# psoc4100smax register map
Vendor: Cypress Semiconductor; Series: PSoC4100Smax; File version: 1.0
CPU: CM0PLUS r0p1, little endian, MPU, no FPU, VTOR, 2 interrupt priority bits
Registers are 32-bit, read-write, reset 0x0 unless marked. A register's access mark holds for its fields unless they carry their own. Offsets are from the block's base; [hi:lo] are bit positions; {n}, {i} and the like mark numbered series; 'fields as' and 'values as' point back to an identical list.

## MSC0 (part 1 of 2) — MultiSense Controller
Base 0x40290000
Same registers: MSC1 0x402A0000
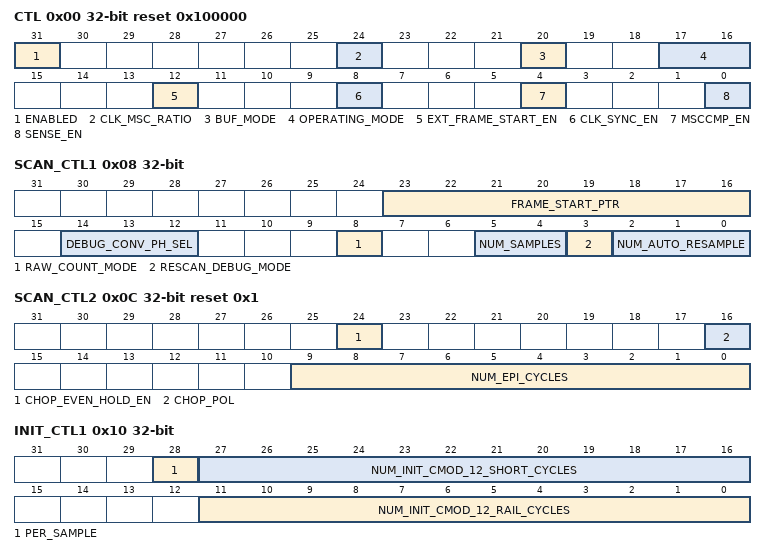
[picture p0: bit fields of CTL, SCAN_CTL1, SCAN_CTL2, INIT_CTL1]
0x00 CTL reset 0x100000 — Configuration and Control
  [31] ENABLED — Master enable of the MSCv3 IP. Must be set to '1' for any operation to function. When '0' all analog components are off and all switches are open.
    0=DISABLED (N/A); 1=ENABLED (N/A)
  [24] CLK_MSC_RATIO — Control bit for logic that creates clk_msc from clk_hf. '0': Divided. clk_hf :: clk_msc is at least 2:1 divide ratio. Ratio controlled by clock_msc_pos_en and clock_msc_neg_en provided by PERI. '1': Pass-through. clk_hf :: clk_msc is 1:1.
    0=DIVIDED (N/A); 1=PASSTHROUGH (N/A)
  [20] BUF_MODE — Shield buffer operating mode select. '0': High bandwidth mode. '1': Shield mode.
    0=HIGH_BW_MODE (N/A); 1=SHIELD_MODE (N/A)
  [17:16] OPERATING_MODE — Sequencer FSM Operating Mode '0': CPU Mode. '1': Chained-Scan DMA Mode. '2': Autonomous Scan Multi Sensor Mode. '3': Low Power Always-On-Capsense Mode.
    0=CPU (Frame scan configurations are stored in system RAM. Start of frame initiated by CPU via AHB. After each scan in frame, the end of scan interrupt is raised. The CPU extracts results and programs and starts the next scan. End of frame interrupt is produced so CPU can extract and process data.); 1=CS_DMA (Frame scan configurations are stored in system RAM. CPU writes into DMA registers to start a DMA transfer. i.e. CPU/firmware initiates a DMA transfer to write first scan configuration. The rest of the scans in the frame are chained via trigger to DMA. End of frame interrupt is produced so CPU can extract and process data.); 2=AS_MS (Frame scan configurations are stored in IP RAM. Start of frame initiated by CPU via AHB. The rest of the scans are chained autonomously by Sequencer FSM. End of frame interrupt is produced so CPU can extract and process data.); 3=LP_AOC (Frame scan configurations are stored in IP RAM. Start of frame initiated by LP-AOC timer expire. Rest of the scans are chained autonomously by Sequencer FSM. No end of frame interrupt, no data processing by CPU. Wake up interrupt fired upon valid signal detection (LP-AOC FSM).)
  [12] EXT_FRAME_START_EN — Control bit to enable external frame start of Sequencer FSM via GPIO. '0': FSM is only sensitive to START_FRAME bit. '1': FSM sensitive to external frame start (and not sensitive to START_FRAME). This external start can be a new or pending external frame start event or an indication from the LP-AoC FSM.
    0=DISABLED (N/A); 1=ENABLED (N/A)
  [8] CLK_SYNC_EN — Control bit to create external channel sync clock. '0': msc_ext_sync_clk_out (and _out_en) tied 0. '1': Generate msc_ext_sync_clk_out using clock_sync_pos_en and set msc_ext_sync_clk_out_en = 1.
    0=DISABLED (N/A); 1=ENABLED (N/A)
  [4] MSCCMP_EN — MSC Comparator Enable.
    0=DISABLED (N/A); 1=ENABLED (N/A)
  [0] SENSE_EN — Enables the sense modulator output. '0': All switches, static or dynamic, are open. '1': Switches can be closed/open as per MMIO setting and Sequencer FSM.
    0=DISABLED (N/A); 1=ENABLED (N/A)
0x04 SPARE — Spare MMIO
  [5:0] SPARE — Spare MMIO (Hard IP).
0x08 SCAN_CTL1 — Scan Control 1
  [23:16] FRAME_START_PTR — Pointer to first sensor configuration of a frame. Hardware increments a local pointer from this start point. In LP-AoC mode, hardware returns to this pointer after the frame is complete prior to starting the next frame (after a timeout).
  [14:12] DEBUG_CONV_PH_SEL — Debug counter conversion chop phase select for DEBUG_CONV_COUNT. Must be between 0 and NUM_CONV. The number of conversions (or chop phases) for a given scan is controlled by NUM_CONV. Although only discrete values are possible for NUM_CONV, any conversion index up to this number may be selected up to NUM_CONV. For example if NUM_CONV = 7 (number of conversions is 8), then DEBUG_CONG_PH_SEL can be any value between 0 and 7 to select the particular conversion that the count is required for.
  [8] RAW_COUNT_MODE — Control bit to handle behaviour when RAW_COUNT exceeds 0xFFFF. '0': Saturate. In this scenario, RAW_COUNT is clamped at 0xFFFF and RESULT_FIFO_RD.OVERFLOW is set. '1': Overflow. In this scenario, RAW_COUNT rolls over and RESULT_FIFO_RD.OVERFLOW is set. This mode allows more sensitive tuning if measuring baseline capacitance is a don't care (e.g. SAR use case).
    0=SATURATE (N/A); 1=OVERFLOW (N/A)
  [5:4] NUM_SAMPLES — Number of samples (minus 1) to be scanned. NUM_SAMPLES > 1 results in autonomous scan same sensor (AS-SS) behaviour. Firmware Rule: Usable setting for NUM_SAMPLES is limited depending on the size of the result FIFO. Size of this FIFO determined by CONFIG_NR and SAMPLE_NR. If CONFIG_NR = 0, FIFO size is SAMPLE_NR. If CONFIG_NR > 0, FIFO size is SAMPLE_NR * CONFIG_NR. NUM_SAMPLES must be less than or equal to the FIFO size in debug mode.
  [3] RESCAN_DEBUG_MODE — If this bit is set all results (good and bad) generated by NUM_AUTO_RESAMPLE are stored. Debug feature. Firmware Rule: Usable setting for NUM_AUTO_RESAMPLE is limited depending on the size of the result FIFO. Size of this FIFO determined by CONFIG_NR and SAMPLE_NR. If CONFIG_NR = 0, FIFO size is SAMPLE_NR. If CONFIG_NR > 0, FIFO size is SAMPLE_NR * CONFIG_NR. NUM_AUTO_RESAMPLE must be less than or equal to the FIFO size in debug mode.
    0=DISABLED (N/A); 1=ENABLED (N/A)
  [2:0] NUM_AUTO_RESAMPLE — If Sequencer detects a bad conversion and NUM_AUTO_RESAMPLE != 0, it will not store the bad result. Instead, it will automatically re-sample using current configuration without firmware intervention. This process repeats until a good conversion is produced or until the programmed maximum. If bad samples are produces for each programmed re-sample attempt, the final bad sample is stored.
0x0C SCAN_CTL2 reset 0x1 — Scan Control 2
  [24] CHOP_EVEN_HOLD_EN — Use this bit to hold the chop value at the end of every even chop phase of NUM_CONV.
    0=DISABLED (N/A); 1=ENABLED (N/A)
  [16] CHOP_POL — Polarity of first chop phase. Hardware updates chop control locally from this point (via inversion and following CHOP_EVEN_HOLD_EN programming also).
  [9:0] NUM_EPI_CYCLES — Number of clk_mod cycles to be run during EPILOGUE. Note that setting this register to 0 is an illegal configuration. This guarantees at least 1 clk_mod cycle during EPILOGUE (required to help timing closure in Sequencer FSM).
0x10 INIT_CTL1 — Initialisation Control 1
  [28] PER_SAMPLE — Decides if coarse initialisation is done per sample when NUM_SAMPLES > 0 (i.e. more than one sample per scan). Applies to CMOD_SEL selected Cmod.
    0=DISABLED (N/A); 1=ENABLED (N/A)
  [27:16] NUM_INIT_CMOD_12_SHORT_CYCLES — Duration of the coarse short phase (shorting Cmod1 and Cmod2 in full-wave mode). Programmed in terms of clk_mod cycles. Should be set to zero in the case of half-wave mode.
  [11:0] NUM_INIT_CMOD_12_RAIL_CYCLES — Duration of the coarse initialisation phase (e.g. connecting Cmod1 to vdda and Cmod2 to vssa in full-wave mode). Programmed in terms of clk_mod cycles.
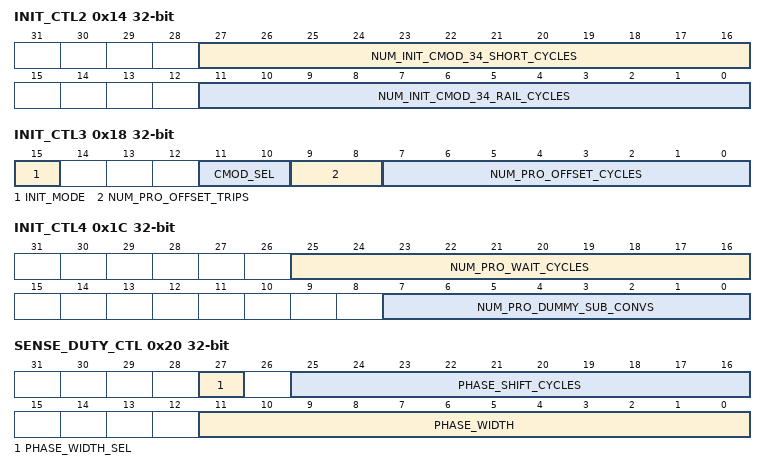
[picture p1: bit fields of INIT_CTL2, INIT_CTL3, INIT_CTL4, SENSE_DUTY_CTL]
0x14 INIT_CTL2 — Initialisation Control 2
  [27:16] NUM_INIT_CMOD_34_SHORT_CYCLES — Duration of the coarse short phase (shorting Cmod3 and Cmod4 in full-wave mode). Programmed in terms of clk_mod cycles. Should be set to zero in the case of half-wave mode.
  [11:0] NUM_INIT_CMOD_34_RAIL_CYCLES — Duration of the coarse initialisation phase (e.g. connecting Cmod3 to vdda and Cmod4 to vssa in full-wave mode). Programmed in terms of clk_mod cycles.
0x18 INIT_CTL3 — Initialisation Control 3
  [15] INIT_MODE — Determines autonomous initialisation behaviour during INIT_CMOD. 0: Decode CMOD_SEL. CMOD_12: S1CV = 1, S2CG = 1 CMOD_34: S3CV = 1, S4CG = 1 CMOD_1: S1CV = 1 CMOD_3: S3CV = 1 1: Decode CMOD_SEL. Should be CMOD_1 or CMOD_3. Firmware Rule: Firmware should also close CBSO, FSP and one of BGRF/RMF/MBF to select type of reference. CMOD_1: C1CB = 1 CMOD_3: C3CB = 1
    0=REFERENCE_VDDA (Used for full and half wave when Vdda is reference.); 1=REFERENCE_VREF (Used for half-wave when Vref is reference.)
  [11:10] CMOD_SEL — Select which Cmod are used and the cycle thresholds to be used for coarse initialisation. Note this field affects which Cmod switches are autonomously initialised by hardware as well as influencing the cycle counters as per INIT_MODE. '0' || '2': Use NUM_INIT_CMOD_12_RAIL_CYCLES and NUM_INIT_CMOD_12_SHORT_CYCLES '1' || '3': Use NUM_INIT_CMOD_34_RAIL_CYCLES and NUM_INIT_CMOD_34_SHORT_CYCLES Firmware Rule: Firmware must program the appropriate SNS_SW_SEL_CMODx.ENABLED bits to match the Cmod selected with CMOD_SEL. Firmware must also set a valid INIT_MODE with CMOD_SEL.
    0=CMOD_12 (Used for full-wave); 1=CMOD_34 (Used for full-wave); 2=CMOD_1 (Used for half-wave); 3=CMOD_3 (Used for half-wave)
  [9:8] NUM_PRO_OFFSET_TRIPS — Number of comparator trips required to be observed in PRO_OFFSET before proceeding to dummy cycles. Note that a 'trip' is defined as a change of state of the comparator (either a 0 to 1 or a 1 to 0 transition). A trip at the very start of PRO_OFFSET is considered a trip with respect to this count.
  [7:0] NUM_PRO_OFFSET_CYCLES — Maximum number of clk_mod cycles to be assigned for the PRO_OFFSET state. If NUM_PRO_OFFSET_TRIPS are observed before this timeout, exit at that point. Programming combinations: a) OFFSET_CYCLES == 0 && OFFSET_TRIPS == 0 -> Skip PRO_OFFSET b) OFFSET_CYCLES == 0 && OFFSET_TRIPS > 0 -> wait in PRO_OFFSET for OFFSET_TRIPS c) OFFSET_CYCLES > 0 && OFFSET_TRIPS == 0 -> wait in PRO_OFFSET for OFFSET_CYCLES d) OFFSET_CYCLES > 0 && OFFSET_TRIPS > 0 -> wait in PRO_OFFSET for the first of OFFSET_CYCLES and OFFSET_TRIPS. Note that if OFFSET_TRIPS > 0: i) SW_COTCA and SW_COCB autonomously adjust as per their description after each comparator trip apart from the last trip. Expect OFFSET_TRIPS-1 adjustments in PRO_OFFSET. ii) If FINE_MODE == COMPENSATION SW_CFTCA and SW_CFTCB autonomously swap settings after each comparator trip apart from the last trip. Expect OFFSET_TRIPS-1 adjustments in PRO_OFFSET. iii) For both sets of switches above, after the last trip the switches revert to their programmed MMIO setting when exiting PRO_OFFSET. If OFFSET_TRIPS == 0 and OFFSET_CYCLES > 0: Intention is that PRO_OFFSET be a fixed duration. The autonomous behaviour for this case is the same as the OFFSET_TRIPS > 0 case, except that the number of trips (and hence the number of adjustments for (i) and (ii) above) are unknown in advance. At the end of OFFSET_CYCLES, the switches revert to their programmed MMIO setting when exiting PRO_OFFSET.
0x1C INIT_CTL4 — Initialisation Control 4
  [25:16] NUM_PRO_WAIT_CYCLES — Number of clk_mod cycles to be run during PRO_WAIT. Firmware Rule: If chopping is enabled (NUM_CONV > ONE), then NUM_PRO_WAIT_CYCLES must be >=1.
  [7:0] NUM_PRO_DUMMY_SUB_CONVS — Number of sub-conversions (dummy cycles) to be run during PRO_DUMMY. Firmware Rule: If chopping is enabled (NUM_CONV > ONE), then NUM_PRO_DUMMY_SUB_CONVS must be >=1.
0x20 SENSE_DUTY_CTL — Sense Clock Duty Cycle Control
  [27] PHASE_WIDTH_SEL — Select which phases the PHASE_WIDTH applies to: '0': PHASE_WIDTH corresponds to width of ph0 and ph2. '1': PHASE_WIDTH corresponds to width of ph1 and ph3.
    0=PH0_AND_PH2 (N/A); 1=PH1_AND_PH3 (N/A)
  [25:16] PHASE_SHIFT_CYCLES — Phase shift cycle control for ph0X and ph1X. Must be > 0 if PHASE_SHIFT_EN = 1.
  [11:0] PHASE_WIDTH — Control width (clk_mod cycles) of ph0 and ph2 OR ph1 and ph3. If set to zero, Fs is divided equally between all phases. This field is only applicable when LFSR_MODE = DIRECT_CLOCK.
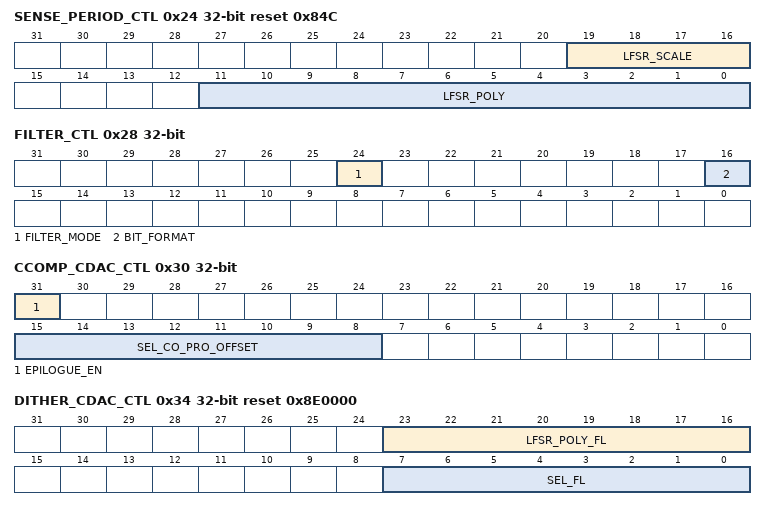
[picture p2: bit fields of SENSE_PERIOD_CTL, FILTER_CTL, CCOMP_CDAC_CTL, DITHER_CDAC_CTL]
0x24 SENSE_PERIOD_CTL reset 0x84C — Sense Clock Period Control
  [19:16] LFSR_SCALE — Shift the LFSR output left by LSFR_SCALE bits before adding to SENSE_DIV. This scaling is only applicable in spread spectrum mode. Note that the clock divider including the dithering term must fit in 12 bits, otherwise the result is undefined.
  [11:0] LFSR_POLY — Programmable polynomial to be used for the sense LFSR. For example (default): G(x) = X^12 + X^7 + X^4 + X^3 + 1 LFSR_POLY = 0x84C (1000_0100_1100). Note that LFSR_POLY[i] = 1 if X^(i+1) is included in the polynomial. The +1 feedback term is implied and doesn't need a programmable bit.
0x28 FILTER_CTL — Filter Control
  [24] FILTER_MODE
    0=CIC1 (Use the standard first order counter low pass filter (equivalent to CIC1). Scan Time = 2^M Number of CIC1 sub-samples = 1 Time for first valid CIC1 sub-sample = 2^M Number of valid CIC1 sub-samples = 1 CIC1 Scan Resolution = 2^M = N); 1=CIC2 (Use CIC2 Filter. Advantage of CIC2 over CIC1 is a higher resolution result for an equivalent scan time. All valid sub-samples are averaged to achieve an overall sample result for the scan. Interrupt is fired for every valid sub-sample to facilitate debug of the individual sub-samples. Scan Time = 2^M Number of CIC2 sub-samples = (2^M)/N Time for first valid CIC2 sub-sample = 2N Number of valid CIC2 sub-samples = ((2^M)/N) - 1 CIC2 Scan Resolution = N^2)
  [16] BIT_FORMAT — Determines how the synchronised comparator output is interpreted by the filter pipeline. Firmware Rule: When FILTER_MODE = CIC1, BIT_FORMAT should be UNSIGNED.
    0=UNSIGNED (Input values [0,+1]); 1=SIGNED (Input values [-1,+1]. In this scenario a value of 0 is interpreted as -1.)
0x30 CCOMP_CDAC_CTL — Compensation CAPDAC Control
  [31] EPILOGUE_EN — Control on whether Ccomp is active during EPILOGUE for final balancing in a conversion. Note that for this bit to enable Ccomp during EPILOGUE, need SEL_CO > 0 or FINE_MODE = COMPENSATION.
    0=DISABLED (N/A); 1=ENABLED (N/A)
  [15:8] SEL_CO_PRO_OFFSET — Select value for Compensation CAPDAC size during PRO_OFFSET until the first comparator trip is observed. Otherwise SEL_CO applies.
0x34 DITHER_CDAC_CTL reset 0x8E0000 — Flatspot/Dither CAPDAC Switch Control
  [23:16] LFSR_POLY_FL — Dither/Flatspot CAPDAC LFSR polynomial. Uses same encoding as the spread spectrum polynomial LFSR_POLY. For example (default): G(x) = X^8 + X^4 + X^3 + X^2 + 1 LFSR_POLY_FL = 0x8E (1000_1110). Note that LFSR_POLY_FL[i] = 1 if X^(i+1) is included in the polynomial. The +1 feedback term is implied and doesn't need a programmable bit.
  [7:0] SEL_FL — Select value for Dither/Flatspot CAPDAC size. If dithering is enabled (FL_EN = 1), this is the seed value for the LFSR. If dithering is disabled, this value is presented directly to the hard IP as the CAPDAC code.
0x40 CSW_CTL — Control Mux Switch Control
  [31:0] CSW_FUNC_MODE — Select between SW_SEL_CSW[x] and SW_SEL_CSW_FUNC. CSW_FUNC_MODE[x] = 0: Use SW_CSW_CTL for control MUX x. CSW_FUNC_MODE[x] = 1: Use SW_SEL_CSW_FUNC[y] for control MUX x as selected by y = {SW_SEL_CSW_MASK2[x],SW_SEL_CSW_MASK1[x],SW_SEL_CSW_MASK0[x]}.
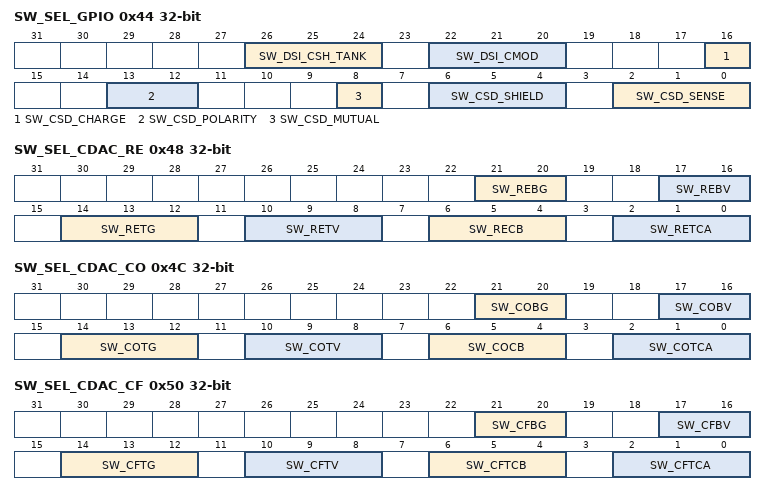
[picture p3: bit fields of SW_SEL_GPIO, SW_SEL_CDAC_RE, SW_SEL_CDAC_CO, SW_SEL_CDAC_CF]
0x44 SW_SEL_GPIO — GPIO Switch Control
  [26:24] SW_DSI_CSH_TANK — MUX select for dsi_csh_tank waveform. if CMOD_SEL = CMOD_12 | CMOD_1 dsi_csh_tank[0] = Decode SW_DSI_CSH_TANK to select appropriate dsi_csh_tank waveform. dsi_csh_tank[1] = 0. if CMOD_SEL = CMOD_34 | CMOD_3 dsi_csh_tank[0] = 0. dsi_csh_tank[1] = Decode SW_DSI_CSH_TANK to select appropriate dsi_csh_tank waveform. This is assuming that: dsi_csh_tank[0] is routed to cmod2 dsi_csh_tank[1] is routed to cmod4 Note that hardware overrides MMIO setting for dsi_csh_tank and sets it 1 during the INIT_SHORT state if using GPIO sensors (SW_DSI_CMOD != OPEN || SW_DSI_CSHTANK != OPEN).
    0=LOGIC_0 (N/A); 1=LOGIC_1 (N/A); 2=CHOP_PH0_PH1 (chop == 1 ? ph0 : ph1); 3=CHOP_PH1_PH3 (chop == 1 ? ph1 : ph3); 4=PH1 (N/A)
  [22:20] SW_DSI_CMOD — MUX select for dsi_cmod waveform. if CMOD_SEL = CMOD_12 | CMOD_1 dsi_cmod[0] = Decode SW_DSI_CMOD to select appropriate dsi_cmod waveform. dsi_cmod[1] = 0. if CMOD_SEL = CMOD_34 | CMOD_3 dsi_cmod[0] = 0. dsi_cmod[1] = Decode SW_DSI_CMOD to select appropriate dsi_cmod waveform. This is assuming that: dsi_cmod[0] is routed to cmod1 dsi_cmod[1] is routed to cmod3 Note that hardware overrides MMIO setting for dsi_cmod and sets it 1 during the INIT_SHORT state if using GPIO sensors (SW_DSI_CMOD != OPEN || SW_DSI_CSHTANK != OPEN).
    0=LOGIC_0 (N/A); 1=LOGIC_1 (N/A); 2=CHOP_PH1_PH0 (chop == 1 ? ph1 : ph0); 3=CHOP_PH3_PH1 (chop == 1 ? ph3 : ph1); 4=PH0 (N/A)
  [16] SW_CSD_CHARGE — MUX select for csd_charge waveform.
    0=LOGIC_0 (N/A); 1=LOGIC_1 (N/A)
  [13:12] SW_CSD_POLARITY — MUX select for csd_polarity waveform.
    0=LOGIC_0 (N/A); 1=LOGIC_1 (N/A); 2=PH0_OR_PH1 (N/A)
  [8] SW_CSD_MUTUAL — MUX select for csd_mutual waveform.
    0=LOGIC_0 (N/A); 1=LOGIC_1 (N/A)
  [6:4] SW_CSD_SHIELD — MUX select for csd_shield waveform.
    0=LOGIC_0 (N/A); 1=LOGIC_1 (N/A); 2=PH0 (N/A); 3=PH1 (N/A); 4=PH0_OR_PH3 (N/A); 5=PH0_OR_FS2PH1_AND_PH1_OR_PH3 (ph0 || [Fs2_ph1 && (ph1 || ph3)]); 6=PH1X (N/A)
  [2:0] SW_CSD_SENSE — MUX select for csd_sense waveform.
    0=LOGIC_0 (N/A); 1=LOGIC_1 (N/A); 2=PH0 (N/A); 3=PH1 (N/A); 4=PH0_OR_PH3 (N/A); 5=PH0X (N/A); 6=PH1X (N/A)
0x48 SW_SEL_CDAC_RE — Reference CAPDAC Switch Control
  [21:20] SW_REBG — Reference CAPDAC bottom plate to vssa_q Switch. Firmware Rule: Do not program REBV and REBG such that they are closed simultaneously.
    0=OPEN (sel = 00); 1=CLOSED (sel = 01); 2=CLK (sel = 10 (clk_reffb)); 3=CLK_BAR (sel = 11 (!clk_reffb))
  [17:16] SW_REBV — Reference CAPDAC bottom plate to vdda_q Switch. Firmware Rule: Do not program REBV and REBG such that they are closed simultaneously.
    values as SW_REBG
  [14:12] SW_RETG — Reference CAPDAC top plate to vssa_q Switch. Firmware Rule: Do not program RETV and RETG such that they are closed simultaneously.
    0=OPEN (sel = 00); 1=CLOSED (sel = 01); 2=CLK (sel = 10 (clk_reffb)); 3=CLK_BAR (sel = 11 (!clk_reffb)); 4=PH0 (DFT mode); 5=PH2 (DFT mode)
  [10:8] SW_RETV — Reference CAPDAC top plate to vdda_q Switch. Firmware Rule: Do not program RETV and RETG such that they are closed simultaneously.
    values as SW_RETG
  [6:4] SW_RECB — Reference CAPDAC to CSD Bus B Switch
    0=OPEN (sel = 00); 1=CLOSED (sel = 01); 2=CHOP_CLK_BAR (chop == 0 ? sel = 10 (clk_reffb) : sel = 11 (!clk_reffb)); 3=CHOP_CLK (chop == 1 ? sel = 10 (clk_reffb) : sel = 11 (!clk_reffb)); 4=PH1 (DFT mode (ph1 ? sel = 01 : sel = 00)); 5=PH3 (DFT mode (ph3 ? sel = 01 : sel = 00))
  [2:0] SW_RETCA — Reference CAPDAC top plate to CSD Bus A Switch
    values as SW_RECB
0x4C SW_SEL_CDAC_CO — Compensation CAPDAC Switch Control
  [21:20] SW_COBG — Compensation CAPDAC bottom plate to vssa_q Switch. Firmware Rule: Do not program COBV and COBG such that they are closed simultaneously.
    0=OPEN (sel = 00); 1=CLOSED (sel = 01); 2=CLK (sel = 10 (clk_comp)); 3=CLK_BAR (sel = 11 (!clk_comp))
  [17:16] SW_COBV — Compensation CAPDAC bottom plate to vdda_q Switch. Firmware Rule: Do not program COBV and COBG such that they are closed simultaneously.
    values as SW_COBG
  [14:12] SW_COTG — Compensation CAPDAC top plate to vssa_q Switch. Firmware Rule: Do not program COTV and COTG such that they are closed simultaneously.
    values as SW_SEL_CDAC_RE.SW_RETG
  [10:8] SW_COTV — Compensation CAPDAC top plate to vdda_q Switch. Firmware Rule: Do not program COTV and COTG such that they are closed simultaneously.
    values as SW_SEL_CDAC_RE.SW_RETG
  [6:4] SW_COCB — Compensation CAPDAC to CSD Bus B Switch. Note during the PRO_OFFSET state the following autonomous overriding occurs: (compout_sync ^ CHOP_POL) ? [sel = 10 (clk_comp) ] : [sel = 11 (!clk_comp)]. Note that the CHOP_POL above is the hardware copy of the current chop polarity.
    0=OPEN (sel = 00); 1=CLOSED (sel = 01); 2=CHOP_CLK_BAR (chop == 0 ? sel = 10 (clk_comp) : sel = 11 (!clk_comp)); 3=CHOP_CLK (chop == 1 ? sel = 10 (clk_comp) : sel = 11 (!clk_comp)); 4=PH1 (DFT mode (ph1 ? sel = 01 : sel = 00)); 5=PH3 (DFT mode (ph3 ? sel = 01 : sel = 00))
  [2:0] SW_COTCA — Compensation CAPDAC top plate to CSD Bus A Switch. Note during the PRO_OFFSET state the following autonomous overriding occurs: (compout_sync ^ CHOP_POL) ? [sel = 11 (!clk_comp) ] : [sel = 10 (clk_comp)]. Note that the CHOP_POL above is the hardware copy of the current chop polarity.
    values as SW_COCB
0x50 SW_SEL_CDAC_CF — Fine CAPDAC Switch Control
  [21:20] SW_CFBG — Fine CAPDAC bottom plate to vssa_q Switch. Firmware Rule: Do not program CFBV and CFBG such that they are closed simultaneously.
    0=OPEN (sel = 00); 1=CLOSED (sel = 01); 2=CLK (FINE_MODE == REFERENCE ? sel = 10 (clk_reffb) : sel = 10 (clk_comp)); 3=CLK_BAR (FINE_MODE == REFERENCE ? sel = 11 (!clk_reffb) : sel = 11 (!clk_comp))
  [17:16] SW_CFBV — Fine CAPDAC bottom plate to vdda_q Switch. Firmware Rule: Do not program CFBV and CFBG such that they are closed simultaneously.
    values as SW_CFBG
  [14:12] SW_CFTG — Fine CAPDAC top plate to vssa_q Switch. Firmware Rule: Do not program CFTV and CFTG such that they are closed simultaneously.
    0=OPEN (sel = 00); 1=CLOSED (sel = 01); 2=CLK (sel = 10 [(FINE_MODE == REFERENCE) ? clk_reffb : clk_comp]); 3=CLK_BAR (sel = 11 [(FINE_MODE == REFERENCE) ? !clk_reffb : !clk_comp]); 4=PH0 (DFT mode (ph0 ? sel = 01 : sel = 00)); 5=PH2 (DFT mode (ph2 ? sel = 01 : sel = 00))
  [10:8] SW_CFTV — Fine CAPDAC top plate to vdda_q Switch. Firmware Rule: Do not program CFTV and CFTG such that they are closed simultaneously.
    values as SW_CFTG
  [6:4] SW_CFTCB — Fine CAPDAC top plate to CSD Bus B Switch. Note during the PRO_OFFSET state the following autonomous overriding occurs if FINE_MODE = COMPENSATION: (compout_sync ^ CHOP_POL) ? [sel = 10 (clk_comp) ] : [sel = 11 (!clk_comp)]. Note that the CHOP_POL above is the hardware copy of the current chop polarity.
    0=OPEN (sel = 00); 1=CLOSED (sel = 01); 2=CHOP_CLK_BAR (case({chop,FINE_MODE}) {1,REFERENCE} : sel = 11 (!clk_reffb) {1,COMPENSATION} : sel = 11 (!clk_comp) {0,REFERENCE} : sel = 10 (clk_reffb) {0,COMPENSATION} : sel = 10 (clk_comp)); 3=CHOP_CLK (case({chop,FINE_MODE}) {1,REFERENCE} : sel = 10 (clk_reffb) {1,COMPENSATION} : sel = 10 (clk_comp) {0,REFERENCE} : sel = 11 (!clk_reffb) {0,COMPENSATION} : sel = 11 (!clk_comp)); 4=PH1 (DFT mode (ph1 ? sel = 01 : sel = 00)); 5=PH3 (DFT mode (ph3 ? sel = 01 : sel = 00))
  [2:0] SW_CFTCA — Fine CAPDAC top plate to CSD Bus A Switch. Note during the PRO_OFFSET state the following autonomous overriding occurs if FINE_MODE = COMPENSATION: (compout_sync ^ CHOP_POL) ? [sel = 11 (!clk_comp) ] : [sel = 10 (clk_comp)]. Note that the CHOP_POL above is the hardware copy of the current chop polarity.
    values as SW_CFTCB
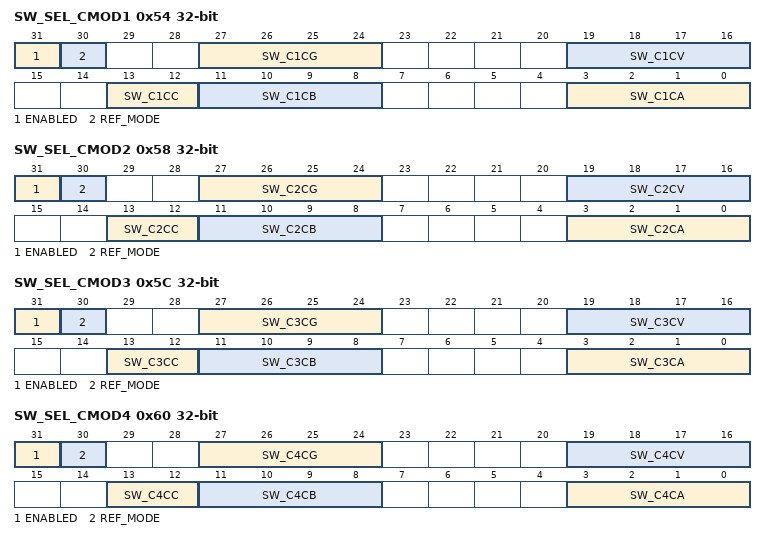
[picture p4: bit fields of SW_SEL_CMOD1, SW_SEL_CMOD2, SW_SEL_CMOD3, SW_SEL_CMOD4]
0x54 SW_SEL_CMOD1 — CMOD Switch Control 1
  [31] ENABLED — CMOD1 enable. Firmware Rule: 1) If any of C1CA/C1CB/C1CC can be 1 (statically or dynamically), ENABLED must be 1. 2) If statically closing (using CLOSED setting) any of C1CA/C1CB/C2CC, ENABLE must be set to 1 in a previous bus access to ensure break-before-make. When re-opening from static CLOSED, C1CA/C1CB/C1CC must be opened in a previous bus access before clearing ENABLE to 0. This is not required for dynamic programming options since e.g. PH0 is not active when these registers are programmed. 3) In any use case where C1CA/C1CB/C1CC are required to be set CLOSED via autonomous scanning, rule (2) cannot be observed. Example use case below**. In this scenario to get the desired effect, the options are to either: a) Dedicate a specific CSW sensor for this purpose, follow rule (2) and do not change the settings autonomously for this sensor. b) Use unused Cmod switches (e.g. if Cmod1/2 are being used, use the switches for Cmod3/4). ** Any use case where a csdbusa/b/c is not used. For example FW CSX wherein csdbusc not used; then csdbusc is statically connected to vssa_sc (C1CG=CLOSED, ENABLED=1 and C1CC=CLOSED).
    0=DISABLED (N/A); 1=ENABLED (N/A)
  [30] REF_MODE — CMOD1 is used as a reference in scenario where CMOD can be re-purposed when not used as a CMOD.
    0=DISABLED (N/A); 1=ENABLED (N/A)
  [27:24] SW_C1CG — CMOD1 to vssa_q Switch. Firmware Rule: Do not program C1CV and C1CG such that they are closed simultaneously.
    0=OPEN (N/A); 1=CLOSED (N/A); 2=PH0 (N/A); 3=PH1 (N/A); 4=PH2 (N/A); 5=PH1_OR_PH3 (N/A); 6=PH2_OR_PH3 (N/A); 7=PH0X (N/A); 8=PH1X (N/A); 9=PH2_OR_FS2PH1_AND_PH1_OR_PH3 (ph2 || [Fs2_ph1 && (ph1 || ph3)]); 10=CLK_BAR (clk_extfb_bar)
  [19:16] SW_C1CV — CMOD1 to vdda_q Switch. Firmware Rule: Do not program C1CV and C1CG such that they are closed simultaneously.
    0=OPEN (N/A); 1=CLOSED (N/A); 2=PH0 (N/A); 3=PH1 (N/A); 4=PH2 (N/A); 5=PH0_OR_PH1 (N/A); 6=PH0X (N/A); 7=PH1X (N/A); 8=PH0_OR_FS2PH0_AND_PH1_OR_PH3 (ph0 || [Fs2_ph0 && (ph1 || ph3)]); 9=CLK (clk_extfb)
  [13:12] SW_C1CC — CMOD1 to CSD Bus C Switch. Firmware Rule: See rule for ENABLED.
    0=OPEN (N/A); 1=CLOSED (N/A); 2=PH1_OR_PH3 (N/A)
  [11:8] SW_C1CB — CMOD1 to CSD Bus B Switch. Firmware Rule: See rule for ENABLED.
    0=OPEN (N/A); 1=CLOSED (N/A); 2=CHOP_TWO_PHASE (chop == 0 ? ph1 : ph0); 3=CHOP_FOUR_PHASE (chop == 0 ? ph3 : ph1); 4=CHOP_MPSC_D (chop == 0 ? ph1 : ph3); 5=CHOP_MPRX (chop == 0 ? ph0 : ph1); 6=PH0 (N/A); 7=PH2 (N/A); 8=CHOP_CLK_BAR (chop == 0 ? clk_extfb : clk_extfb_bar); 9=CHOP_CLK (chop == 1 ? clk_extfb : clk_extfb_bar)
  [3:0] SW_C1CA — CMOD1 to CSD Bus A Switch. During INIT_SHORT (used for full-wave scanning) if CMOD_SEL = CMOD_12, hardware sets C1CA = CLOSED. Firmware Rule: See rule for ENABLED.
    0=OPEN (N/A); 1=CLOSED (N/A); 2=CHOP_TWO_PHASE (chop == 0 ? ph0 : ph1); 3=CHOP_FOUR_PHASE (chop == 0 ? ph1 : ph3); 4=CHOP_MPSC_D (chop == 0 ? ph3 : ph1); 5=CHOP_MPRX (chop == 0 ? ph1 : ph0); 6=PH1 (N/A); 7=PH3 (N/A); 8=CHOP_CLK_BAR (chop == 0 ? clk_extfb : clk_extfb_bar); 9=CHOP_CLK (chop == 1 ? clk_extfb : clk_extfb_bar)
0x58 SW_SEL_CMOD2 — CMOD Switch Control 2
  [31] ENABLED — CMOD2 enable. Firmware Rule: 1) If any of C2CA/C2CB/C2CC can be 1 (statically or dynamically), ENABLED must be 1. 2) If statically closing (using CLOSED setting) any of C2CA/C2CB/C2CC, ENABLE must be set to 1 in a previous bus access to ensure break-before-make. When re-opening from static CLOSED, C2CA/C2CB/C2CC must be opened in a previous bus access before clearing ENABLE to 0. This is not required for dynamic programming options since e.g. PH0 is not active when these registers are programmed. 3) In any use case where C2CA/C2CB/C2CC are required to be set CLOSED via autonomous scanning, rule (2) cannot be observed. Example use case below**. In this scenario to get the desired effect, the options are to either: a) Dedicate a specific CSW sensor for this purpose, follow rule (2) and do not change the settings autonomously for this sensor. b) Use unused Cmod switches (e.g. if Cmod1/2 are being used, use the switches for Cmod3/4). ** Any use case where a csdbusa/b/c is not used. For example FW CSX wherein csdbusc not used; then csdbusc is statically connected to vssa_sc (C2CG=CLOSED, ENABLED=1 and C2CC=CLOSED).
    0=DISABLED (N/A); 1=ENABLED (N/A)
  [30] REF_MODE — CMOD2 is used as a reference in scenario where CMOD can be re-purposed when not used as a CMOD.
    0=DISABLED (N/A); 1=ENABLED (N/A)
  [27:24] SW_C2CG — CMOD2 to vssa_q Switch. Firmware Rule: Do not program C2CV and C2CG such that they are closed simultaneously.
    values as SW_SEL_CMOD1.SW_C1CG
  [19:16] SW_C2CV — CMOD2 to vdda_q Switch. Firmware Rule: Do not program C2CV and C2CG such that they are closed simultaneously.
    values as SW_SEL_CMOD1.SW_C1CV
  [13:12] SW_C2CC — CMOD2 to CSD Bus C Switch. Firmware Rule: See rule for ENABLED.
    0=OPEN (N/A); 1=CLOSED (N/A); 2=PH1_OR_PH3 (N/A)
  [11:8] SW_C2CB — CMOD2 to CSD Bus B Switch. Firmware Rule: See rule for ENABLED.
    values as SW_SEL_CMOD1.SW_C1CB
  [3:0] SW_C2CA — CMOD2 to CSD Bus A Switch. During INIT_SHORT (used for full-wave scanning) if CMOD_SEL = CMOD_12, hardware sets C2CA = CLOSED. Firmware Rule: See rule for ENABLED.
    values as SW_SEL_CMOD1.SW_C1CA
0x5C SW_SEL_CMOD3 — CMOD Switch Control 3
  [31] ENABLED — CMOD3 enable. Firmware Rule: 1) If any of C3CA/C3CB/C3CC can be 1 (statically or dynamically), ENABLED must be 1. 2) If statically closing (using CLOSED setting) any of C3CA/C3CB/C3CC, ENABLE must be set to 1 in a previous bus access to ensure break-before-make. When re-opening from static CLOSED, C3CA/C3CB/C3CC must be opened in a previous bus access before clearing ENABLE to 0. This is not required for dynamic programming options since e.g. PH0 is not active when these registers are programmed. 3) In any use case where C3CA/C3CB/C3CC are required to be set CLOSED via autonomous scanning, rule (2) cannot be observed. Example use case below**. In this scenario to get the desired effect, the options are to either: a) Dedicate a specific CSW sensor for this purpose, follow rule (2) and do not change the settings autonomously for this sensor. b) Use unused Cmod switches (e.g. if Cmod1/2 are being used, use the switches for Cmod3/4). ** Any use case where a csdbusa/b/c is not used. For example FW CSX wherein csdbusc not used; then csdbusc is statically connected to vssa_sc (C3CG=CLOSED, ENABLED=1 and C3CC=CLOSED).
    0=DISABLED (N/A); 1=ENABLED (N/A)
  [30] REF_MODE — CMOD3 is used as a reference in scenario where CMOD can be re-purposed when not used as a CMOD.
    0=DISABLED (N/A); 1=ENABLED (N/A)
  [27:24] SW_C3CG — CMOD3 to vssa_q Switch. Firmware Rule: Do not program C3CV and C3CG such that they are closed simultaneously.
    values as SW_SEL_CMOD1.SW_C1CG
  [19:16] SW_C3CV — CMOD3 to vdda_q Switch. Firmware Rule: Do not program C3CV and C3CG such that they are closed simultaneously.
    values as SW_SEL_CMOD1.SW_C1CV
  [13:12] SW_C3CC — CMOD3 to CSD Bus C Switch. Firmware Rule: See rule for ENABLED.
    0=OPEN (N/A); 1=CLOSED (N/A); 2=PH1_OR_PH3 (N/A)
  [11:8] SW_C3CB — CMOD3 to CSD Bus B Switch. During INIT_SHORT (used for full-wave scanning) if CMOD_SEL = CMOD_34, hardware sets C3CB = CLOSED. Firmware Rule: See rule for ENABLED.
    values as SW_SEL_CMOD1.SW_C1CB
  [3:0] SW_C3CA — CMOD3 to CSD Bus A Switch. Firmware Rule: See rule for ENABLED.
    values as SW_SEL_CMOD1.SW_C1CA
0x60 SW_SEL_CMOD4 — CMOD Switch Control 4
  [31] ENABLED — CMOD4 enable. Firmware Rule: 1) If any of C4CA/C4CB/C4CC can be 1 (statically or dynamically), ENABLED must be 1. 2) If statically closing (using CLOSED setting) any of C4CA/C4CB/C4CC, ENABLE must be set to 1 in a previous bus access to ensure break-before-make. When re-opening from static CLOSED, C4CA/C4CB/C4CC must be opened in a previous bus access before clearing ENABLE to 0. This is not required for dynamic programming options since e.g. PH0 is not active when these registers are programmed. 3) In any use case where C4CA/C4CB/C4CC are required to be set CLOSED via autonomous scanning, rule (2) cannot be observed. Example use case below**. In this scenario to get the desired effect, the options are to either: a) Dedicate a specific CSW sensor for this purpose, follow rule (2) and do not change the settings autonomously for this sensor. b) Use unused Cmod switches (e.g. if Cmod1/2 are being used, use the switches for Cmod3/4). ** Any use case where a csdbusa/b/c is not used. For example FW CSX wherein csdbusc not used; then csdbusc is statically connected to vssa_sc (C4CG=CLOSED, ENABLED=1 and C4CC=CLOSED).
    0=DISABLED (N/A); 1=ENABLED (N/A)
  [30] REF_MODE — CMOD4 is used as a reference in scenario where CMOD can be re-purposed when not used as a CMOD.
    0=DISABLED (N/A); 1=ENABLED (N/A)
  [27:24] SW_C4CG — CMOD4 to vssa_q Switch. Firmware Rule: Do not program C4CV and C4CG such that they are closed simultaneously.
    values as SW_SEL_CMOD1.SW_C1CG
  [19:16] SW_C4CV — CMOD4 to vdda_q Switch. Firmware Rule: Do not program C4CV and C4CG such that they are closed simultaneously.
    values as SW_SEL_CMOD1.SW_C1CV
  [13:12] SW_C4CC — CMOD4 to CSD Bus C Switch. Firmware Rule: See rule for ENABLED.
    0=OPEN (N/A); 1=CLOSED (N/A); 2=PH1_OR_PH3 (N/A)
  [11:8] SW_C4CB — CMOD4 to CSD Bus B Switch. During INIT_SHORT (used for full-wave scanning) if CMOD_SEL = CMOD_34, hardware sets C4CB = CLOSED. Firmware Rule: See rule for ENABLED.
    values as SW_SEL_CMOD1.SW_C1CB
  [3:0] SW_C4CA — CMOD4 to CSD Bus A Switch. Firmware Rule: See rule for ENABLED.
    values as SW_SEL_CMOD1.SW_C1CA
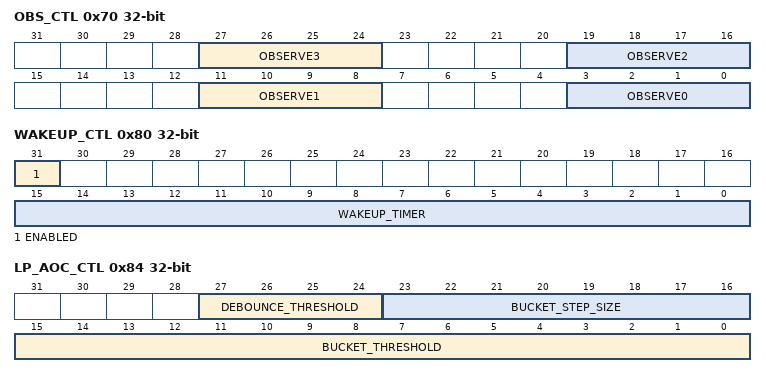
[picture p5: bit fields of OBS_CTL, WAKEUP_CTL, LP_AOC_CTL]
0x70 OBS_CTL — Observability Control
  [27:24] OBSERVE3 — Selects the source for observe output signal 3: 0-14: See OBSERVE0. 15: Sequencer FSM state bit 3.
    0=FS (N/A); 1=COMP_OUT (N/A); 2=COMP_OUT_ADV (N/A); 3=COMP_OUT_SYNC (N/A); 4=COUNTER_LSB (N/A); 5=SCAN_DONE (N/A); {v}=PH{v-6} (N/A) (v=6..9); 10=PH0X (N/A); 11=PH1X (N/A); 12=UNUSED_1 (N/A); 13=UNUSED_2 (N/A); 14=UNUSED_3 (N/A); 15=SM_STATE_3 (N/A)
  [19:16] OBSERVE2 — Selects the source for observe output signal 2: 0-14: See OBSERVE0. 15: Sequencer FSM state bit 2.
    0=FS (N/A); 1=COMP_OUT (N/A); 2=COMP_OUT_ADV (N/A); 3=COMP_OUT_SYNC (N/A); 4=COUNTER_LSB (N/A); 5=SCAN_DONE (N/A); {v}=PH{v-6} (N/A) (v=6..9); 10=PH0X (N/A); 11=PH1X (N/A); 12=UNUSED_1 (N/A); 13=UNUSED_2 (N/A); 14=UNUSED_3 (N/A); 15=SM_STATE_2 (N/A)
  [11:8] OBSERVE1 — Selects the source for observe output signal 1: 0-14: See OBSERVE0. 15: Sequencer FSM state bit 1.
    0=FS (N/A); 1=COMP_OUT (N/A); 2=COMP_OUT_ADV (N/A); 3=COMP_OUT_SYNC (N/A); 4=COUNTER_LSB (N/A); 5=SCAN_DONE (N/A); {v}=PH{v-6} (N/A) (v=6..9); 10=PH0X (N/A); 11=PH1X (N/A); 12=UNUSED_1 (N/A); 13=UNUSED_2 (N/A); 14=UNUSED_3 (N/A); 15=SM_STATE_1 (N/A)
  [3:0] OBSERVE0 — Selects the source for observe output signal 0: 0: Fs 1: Comparator Output (direct from hard IP). 2: Comparator Output captured on clk_hf_adv. 3: Comparator Output captured on clk_mod. 4: Current raw counter LSB. 5: Scan Done (hardware set signal for INTR.SCAN) 6: ph0. 7: ph1. 8: ph2. 9: ph3. 10: ph0X 11: ph1X 12-14: Unused (0). 15: Sequencer FSM state bit 0.
    0=FS (N/A); 1=COMP_OUT (N/A); 2=COMP_OUT_ADV (N/A); 3=COMP_OUT_SYNC (N/A); 4=COUNTER_LSB (N/A); 5=SCAN_DONE (N/A); {v}=PH{v-6} (N/A) (v=6..9); 10=PH0X (N/A); 11=PH1X (N/A); 12=UNUSED_1 (N/A); 13=UNUSED_2 (N/A); 14=UNUSED_3 (N/A); 15=SM_STATE_0 (N/A)
0x80 WAKEUP_CTL — Wakeup Control
  [31] ENABLED — If set, then LP AoC FSM will operate when in DEEP_SLEEP. This also switches clk_hf -> clk_lf.
    0=DISABLED (N/A); 1=ENABLED (N/A)
  [15:0] WAKEUP_TIMER — Timer interval between wakeup scans in LP-AoC mode. Assumes a 32kHz operating clock (clk_lf). Desired range is 1->2000ms.
0x84 LP_AOC_CTL — LP-AoC Control
  [27:24] DEBOUNCE_THRESHOLD — Global threshold for successive TOUCH_THRESHOLD exceeds to warrant a full system wakeup.
  [23:16] BUCKET_STEP_SIZE — Global step size for SENSOR_BASELINE adjustment.
  [15:0] BUCKET_THRESHOLD — Global threshold to control the per sensor SENSOR_BASELINE updates.
